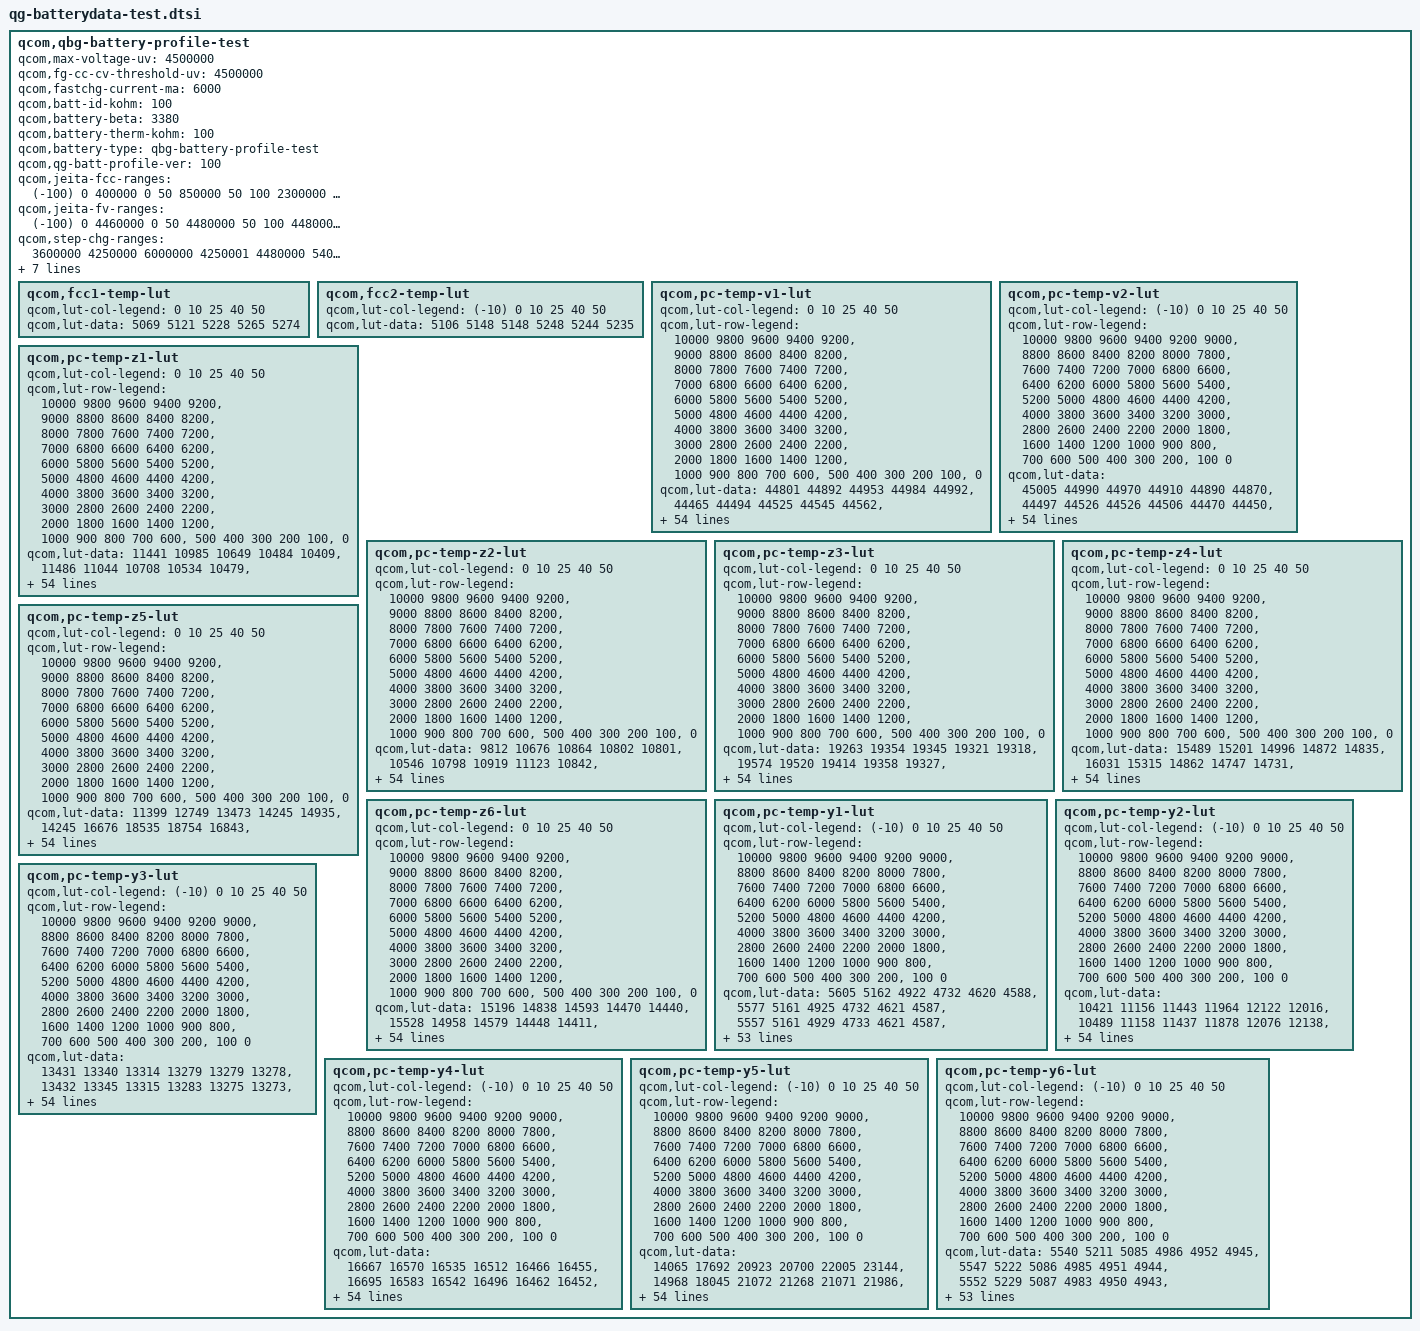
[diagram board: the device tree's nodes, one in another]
qcom,qbg-battery-profile-test {
	/* just test bsttry profile */
	qcom,max-voltage-uv = <4500000>;
	qcom,fg-cc-cv-threshold-uv = <4500000>;
	qcom,fastchg-current-ma = <6000>;
	qcom,batt-id-kohm = <100>;
	qcom,battery-beta = <3380>;
	qcom,battery-therm-kohm = <100>;
	qcom,battery-type = "qbg-battery-profile-test";
	qcom,qg-batt-profile-ver = <100>;

	qcom,jeita-fcc-ranges = <(-100)  0   400000
				0   50   850000
				50  100  2300000
				100 150  3700000
				150 350  6000000
				350 480  6000000
				480 560  2300000
				560 1500 0>;
	qcom,jeita-fv-ranges = <(-100)   0   4460000
				0   50   4480000
				50  100  4480000
				100 150  4480000
				150 350  4450000
				350 480  4450000
				480 560  4100000
				560 1500 4100000>;
	qcom,step-chg-ranges = <3600000  4250000  6000000
				4250001  4480000  5400000
				4480001  4500000  3920000>;
	qcom,vbat-avg-based-step-chg;
	qcom,taper-fcc;

	/* COOL = 15 DegC, WARM = 48 DegC */
	qcom,jeita-soft-thresholds = <0x2554 0x0E8D>;
	/* COLD = -10 DegC, HOT = 56 DegC */
	qcom,jeita-hard-thresholds = <0x43D5 0x0B9B>;
	/* COOL hys = 18 DegC, WARM hys = 45 DegC */
	qcom,jeita-soft-hys-thresholds = <0x225F 0x0FDC>;

	qcom,jeita-soft-fcc-ua = <5400000 2500000>;
	qcom,jeita-soft-fv-uv = <4480000 4100000>;

		qcom,fcc1-temp-lut {
		qcom,lut-col-legend = <0 10 25 40 50>;
		qcom,lut-data = <5069 5121 5228 5265 5274>;
	};

	qcom,fcc2-temp-lut {
		qcom,lut-col-legend = <(-10) 0 10 25 40 50>;
		qcom,lut-data = <5106 5148 5148 5248 5244 5235>;
	};

	qcom,pc-temp-v1-lut {
		qcom,lut-col-legend = <0 10 25 40 50>;
		qcom,lut-row-legend = <10000 9800 9600 9400 9200>,
			<9000 8800 8600 8400 8200>,
			<8000 7800 7600 7400 7200>,
			<7000 6800 6600 6400 6200>,
			<6000 5800 5600 5400 5200>,
			<5000 4800 4600 4400 4200>,
			<4000 3800 3600 3400 3200>,
			<3000 2800 2600 2400 2200>,
			<2000 1800 1600 1400 1200>,
			<1000 900 800 700 600>,
			<500 400 300 200 100>,
			<0>;
		qcom,lut-data = <44801 44892 44953 44984 44992>,
			<44465 44494 44525 44545 44562>,
			<44212 44226 44228 44219 44227>,
			<43979 44010 43989 43970 43971>,
			<43748 43788 43771 43749 43748>,
			<43523 43560 43545 43525 43526>,
			<43285 43328 43312 43289 43292>,
			<43033 43083 43072 43048 43052>,
			<42777 42830 42820 42798 42805>,
			<42522 42576 42561 42542 42552>,
			<42266 42320 42302 42286 42298>,
			<42015 42065 42041 42030 42040>,
			<41767 41814 41787 41777 41784>,
			<41525 41566 41539 41527 41537>,
			<41292 41329 41298 41283 41297>,
			<41066 41100 41063 41048 41062>,
			<40848 40878 40835 40821 40831>,
			<40637 40665 40619 40604 40610>,
			<40436 40461 40415 40396 40400>,
			<40248 40269 40218 40195 40197>,
			<40066 40086 40040 40012 40011>,
			<39882 39896 39859 39835 39834>,
			<39701 39701 39620 39615 39626>,
			<39499 39493 39327 39330 39364>,
			<39231 39235 39098 39095 39133>,
			<38970 38957 38928 38943 38972>,
			<38811 38792 38792 38819 38836>,
			<38698 38700 38690 38704 38708>,
			<38609 38621 38605 38602 38591>,
			<38538 38539 38523 38503 38484>,
			<38477 38461 38443 38407 38389>,
			<38416 38384 38367 38319 38302>,
			<38359 38307 38292 38244 38224>,
			<38303 38240 38223 38176 38152>,
			<38249 38184 38164 38112 38085>,
			<38200 38135 38113 38052 38026>,
			<38159 38094 38066 37993 37960>,
			<38124 38059 38025 37941 37886>,
			<38077 38014 37976 37880 37804>,
			<38012 37944 37893 37793 37716>,
			<37930 37856 37782 37682 37619>,
			<37819 37752 37663 37561 37506>,
			<37677 37624 37530 37426 37369>,
			<37516 37464 37368 37269 37210>,
			<37343 37285 37205 37113 37054>,
			<37176 37122 37096 37017 36965>,
			<37118 37062 37068 36995 36942>,
			<37055 37026 37046 36979 36927>,
			<36991 36979 37024 36953 36903>,
			<36900 36921 36965 36854 36792>,
			<36596 36773 36716 36541 36467>,
			<32672 36361 36259 36058 35980>,
			<31829 32282 35635 35429 35346>,
			<31223 31101 34746 34553 34462>,
			<30548 30360 33258 33127 33037>,
			<30000 30000 30000 30000 30000>;
	};

	qcom,pc-temp-v2-lut {
		qcom,lut-col-legend = <(-10) 0 10 25 40 50>;
		qcom,lut-row-legend = <10000 9800 9600 9400 9200 9000>,
			<8800 8600 8400 8200 8000 7800>,
			<7600 7400 7200 7000 6800 6600>,
			<6400 6200 6000 5800 5600 5400>,
			<5200 5000 4800 4600 4400 4200>,
			<4000 3800 3600 3400 3200 3000>,
			<2800 2600 2400 2200 2000 1800>,
			<1600 1400 1200 1000 900 800>,
			<700 600 500 400 300 200>,
			<100 0>;
		qcom,lut-data = <45005 44990 44970 44910 44890 44870>,
			<44497 44526 44526 44506 44470 44450>,
			<44078 44143 44159 44163 44113 44091>,
			<43775 43865 43890 43896 43836 43811>,
			<43552 43662 43689 43683 43613 43586>,
			<43337 43460 43485 43462 43387 43359>,
			<43103 43232 43257 43224 43149 43121>,
			<42867 42996 43021 42981 42907 42879>,
			<42625 42754 42777 42730 42657 42629>,
			<42375 42504 42523 42473 42401 42374>,
			<42126 42255 42269 42217 42146 42119>,
			<41877 42006 42016 41958 41891 41865>,
			<41631 41758 41766 41704 41639 41615>,
			<41402 41516 41521 41454 41392 41372>,
			<41186 41278 41282 41209 41151 41134>,
			<40965 41050 41049 40973 40919 40902>,
			<40736 40838 40820 40744 40693 40677>,
			<40497 40631 40600 40525 40477 40461>,
			<40238 40421 40396 40317 40271 40254>,
			<39960 40208 40195 40109 40070 40055>,
			<39698 39974 39965 39902 39881 39871>,
			<39457 39691 39701 39692 39691 39691>,
			<39231 39410 39449 39455 39463 39470>,
			<39013 39188 39214 39188 39188 39195>,
			<38806 38994 39001 38966 38965 38967>,
			<38630 38824 38828 38799 38804 38807>,
			<38480 38674 38684 38658 38669 38672>,
			<38353 38537 38553 38532 38547 38551>,
			<38253 38410 38433 38422 38437 38442>,
			<38169 38294 38323 38319 38336 38341>,
			<38094 38187 38222 38222 38245 38247>,
			<38026 38085 38128 38134 38162 38161>,
			<37963 37997 38042 38055 38089 38088>,
			<37901 37932 37962 37982 38020 38019>,
			<37841 37880 37889 37913 37943 37939>,
			<37776 37830 37825 37848 37862 37847>,
			<37706 37783 37765 37776 37772 37747>,
			<37631 37733 37701 37693 37665 37628>,
			<37548 37670 37631 37605 37559 37510>,
			<37457 37596 37551 37516 37470 37417>,
			<37356 37500 37449 37420 37384 37330>,
			<37242 37368 37329 37310 37279 37221>,
			<37120 37222 37186 37181 37157 37097>,
			<36993 37063 37021 37030 37017 36959>,
			<36885 36915 36882 36888 36880 36831>,
			<36780 36801 36805 36843 36854 36802>,
			<36729 36750 36766 36817 36834 36784>,
			<36674 36703 36715 36775 36805 36758>,
			<36660 36651 36646 36696 36747 36696>,
			<36570 36589 36456 36480 36546 36496>,
			<36408 36484 36064 36017 36112 36050>,
			<36289 36266 35471 35355 35521 35476>,
			<35407 36276 34689 34382 34735 34708>,
			<31338 35839 33955 33304 33541 33579>,
			<30264 30665 32502 32805 31731 31656>,
			<29252 29324 28120 29068 27613 27531>;
	};

	qcom,pc-temp-z1-lut {
		qcom,lut-col-legend = <0 10 25 40 50>;
		qcom,lut-row-legend = <10000 9800 9600 9400 9200>,
			<9000 8800 8600 8400 8200>,
			<8000 7800 7600 7400 7200>,
			<7000 6800 6600 6400 6200>,
			<6000 5800 5600 5400 5200>,
			<5000 4800 4600 4400 4200>,
			<4000 3800 3600 3400 3200>,
			<3000 2800 2600 2400 2200>,
			<2000 1800 1600 1400 1200>,
			<1000 900 800 700 600>,
			<500 400 300 200 100>,
			<0>;
		qcom,lut-data = <11441 10985 10649 10484 10409>,
			<11486 11044 10708 10534 10479>,
			<11487 11042 10711 10536 10480>,
			<11488 11052 10706 10528 10475>,
			<11497 11059 10707 10526 10475>,
			<11516 11063 10707 10526 10475>,
			<11520 11066 10704 10526 10475>,
			<11501 11064 10700 10526 10476>,
			<11481 11058 10695 10525 10476>,
			<11473 11053 10691 10522 10477>,
			<11467 11046 10691 10521 10477>,
			<11462 11041 10691 10521 10477>,
			<11458 11038 10692 10522 10478>,
			<11456 11036 10692 10522 10478>,
			<11466 11036 10692 10523 10481>,
			<11485 11038 10694 10525 10483>,
			<11486 11039 10699 10527 10485>,
			<11474 11037 10704 10530 10487>,
			<11467 11035 10710 10532 10489>,
			<11468 11037 10713 10535 10492>,
			<11472 11046 10713 10538 10495>,
			<11476 11053 10713 10541 10499>,
			<11481 11059 10713 10543 10500>,
			<11483 11063 10716 10544 10500>,
			<11479 11063 10719 10545 10501>,
			<11473 11062 10724 10548 10502>,
			<11477 11062 10728 10553 10505>,
			<11493 11068 10731 10556 10508>,
			<11500 11072 10735 10559 10512>,
			<11495 11072 10738 10562 10515>,
			<11489 11070 10741 10565 10518>,
			<11490 11071 10745 10568 10521>,
			<11495 11079 10753 10573 10523>,
			<11496 11083 10759 10578 10525>,
			<11487 11082 10760 10579 10528>,
			<11478 11080 10759 10579 10531>,
			<11487 11080 10759 10579 10534>,
			<11511 11081 10763 10584 10535>,
			<11519 11083 10769 10589 10536>,
			<11511 11083 10777 10592 10538>,
			<11505 11084 10787 10594 10540>,
			<11513 11089 10790 10597 10542>,
			<11525 11099 10791 10602 10544>,
			<11526 11115 10795 10604 10547>,
			<11526 11120 10800 10605 10549>,
			<11541 11109 10803 10609 10552>,
			<11560 11113 10807 10610 10553>,
			<11524 11097 10805 10612 10553>,
			<11524 11102 10805 10615 10554>,
			<11517 11103 10814 10618 10557>,
			<11516 11106 10814 10621 10561>,
			<11528 11099 10825 10625 10567>,
			<11534 11095 10839 10637 10574>,
			<11534 11104 10857 10650 10585>,
			<11534 11104 10857 10650 10585>,
			<11534 11104 10857 10650 10585>;
	};

	qcom,pc-temp-z2-lut {
		qcom,lut-col-legend = <0 10 25 40 50>;
		qcom,lut-row-legend = <10000 9800 9600 9400 9200>,
			<9000 8800 8600 8400 8200>,
			<8000 7800 7600 7400 7200>,
			<7000 6800 6600 6400 6200>,
			<6000 5800 5600 5400 5200>,
			<5000 4800 4600 4400 4200>,
			<4000 3800 3600 3400 3200>,
			<3000 2800 2600 2400 2200>,
			<2000 1800 1600 1400 1200>,
			<1000 900 800 700 600>,
			<500 400 300 200 100>,
			<0>;
		qcom,lut-data = <9812 10676 10864 10802 10801>,
			<10546 10798 10919 11123 10842>,
			<10565 10804 10959 11232 10966>,
			<10582 10736 10881 11082 11273>,
			<10564 10676 10820 11017 11207>,
			<10513 10623 10760 10997 11157>,
			<10470 10579 10691 10996 11171>,
			<10433 10542 10657 10996 11192>,
			<10404 10514 10672 11001 11187>,
			<10387 10514 10698 11018 11158>,
			<10374 10547 10715 11032 11150>,
			<10375 10579 10727 11040 11229>,
			<10403 10597 10744 11051 11302>,
			<10431 10612 10777 11090 11226>,
			<10447 10634 10811 11138 11076>,
			<10461 10661 10833 11116 11053>,
			<10476 10688 10852 11000 11108>,
			<10492 10713 10884 10951 11188>,
			<10510 10736 10940 11026 11353>,
			<10536 10757 10984 11128 11506>,
			<10559 10777 10999 11192 11530>,
			<10561 10782 11014 11250 11538>,
			<10557 10770 11071 11352 11552>,
			<10555 10760 11192 11545 11576>,
			<10558 10762 11229 11640 11610>,
			<10563 10768 11131 11512 11703>,
			<10562 10768 11020 11357 11801>,
			<10559 10751 10964 11375 11798>,
			<10558 10738 10925 11454 11735>,
			<10566 10760 10957 11469 11638>,
			<10576 10796 11161 11363 11416>,
			<10576 10805 11274 11245 11213>,
			<10575 10806 11166 11165 11121>,
			<10575 10807 11037 11106 11061>,
			<10583 10796 11026 11144 11082>,
			<10592 10782 11026 11337 11249>,
			<10592 10782 11030 11510 11472>,
			<10592 10790 11083 11657 11856>,
			<10592 10799 11143 11745 12157>,
			<10595 10805 11185 11737 12145>,
			<10599 10813 11217 11710 12067>,
			<10603 10823 11204 11680 11932>,
			<10608 10836 11140 11638 11666>,
			<10654 10850 11126 11442 11587>,
			<10659 10946 11134 11200 11559>,
			<10552 11111 11206 11274 11489>,
			<9889 11087 11180 11259 11528>,
			<9815 11033 11121 11282 11525>,
			<9735 10981 11080 11333 11734>,
			<10057 10901 11065 11521 11696>,
			<11666 10812 11261 11177 11100>,
			<65535 10708 11152 10851 10842>,
			<65535 65535 10747 10737 10849>,
			<9707 10720 10599 10612 10799>,
			<9707 10720 10599 10612 10799>,
			<9707 10720 10599 10612 10799>;
	};

	qcom,pc-temp-z3-lut {
		qcom,lut-col-legend = <0 10 25 40 50>;
		qcom,lut-row-legend = <10000 9800 9600 9400 9200>,
			<9000 8800 8600 8400 8200>,
			<8000 7800 7600 7400 7200>,
			<7000 6800 6600 6400 6200>,
			<6000 5800 5600 5400 5200>,
			<5000 4800 4600 4400 4200>,
			<4000 3800 3600 3400 3200>,
			<3000 2800 2600 2400 2200>,
			<2000 1800 1600 1400 1200>,
			<1000 900 800 700 600>,
			<500 400 300 200 100>,
			<0>;
		qcom,lut-data = <19263 19354 19345 19321 19318>,
			<19574 19520 19414 19358 19327>,
			<19641 19556 19448 19354 19327>,
			<19678 19564 19482 19406 19371>,
			<19691 19571 19487 19409 19375>,
			<19699 19578 19487 19409 19376>,
			<19706 19582 19484 19406 19375>,
			<19714 19581 19479 19400 19372>,
			<19718 19578 19467 19394 19367>,
			<19715 19572 19453 19387 19357>,
			<19706 19550 19446 19380 19353>,
			<19696 19532 19442 19373 19353>,
			<19682 19525 19437 19366 19352>,
			<19667 19520 19427 19362 19345>,
			<19655 19511 19416 19358 19331>,
			<19644 19500 19409 19351 19326>,
			<19634 19491 19403 19337 19324>,
			<19627 19484 19396 19329 19323>,
			<19619 19480 19385 19326 19321>,
			<19609 19478 19379 19324 19318>,
			<19601 19477 19376 19322 19315>,
			<19601 19477 19375 19321 19311>,
			<19607 19483 19382 19323 19311>,
			<19615 19491 19404 19336 19313>,
			<19633 19498 19411 19343 19315>,
			<19651 19505 19402 19328 19305>,
			<19651 19505 19389 19310 19290>,
			<19644 19489 19378 19309 19303>,
			<19636 19477 19368 19312 19350>,
			<19629 19477 19367 19318 19367>,
			<19622 19477 19374 19347 19359>,
			<19617 19479 19383 19367 19347>,
			<19614 19494 19401 19362 19338>,
			<19612 19503 19418 19352 19330>,
			<19612 19501 19416 19346 19323>,
			<19612 19497 19407 19341 19316>,
			<19610 19492 19398 19337 19314>,
			<19606 19486 19390 19335 19318>,
			<19601 19480 19385 19334 19322>,
			<19594 19477 19384 19335 19322>,
			<19586 19474 19384 19338 19321>,
			<19578 19465 19383 19337 19318>,
			<19567 19452 19381 19333 19310>,
			<19550 19446 19379 19326 19313>,
			<19455 19432 19375 19320 19320>,
			<19341 19407 19359 19318 19304>,
			<19273 19406 19357 19315 19302>,
			<19274 19335 19350 19310 19298>,
			<19277 19313 19331 19305 19287>,
			<19316 19313 19323 19302 19287>,
			<19524 19428 19308 19309 19313>,
			<19265 19441 19305 19329 19325>,
			<19260 19263 19324 19334 19327>,
			<21204 20903 19399 19336 19328>,
			<21204 20903 19399 19336 19328>,
			<21204 20903 19399 19336 19328>;
	};

	qcom,pc-temp-z4-lut {
		qcom,lut-col-legend = <0 10 25 40 50>;
		qcom,lut-row-legend = <10000 9800 9600 9400 9200>,
			<9000 8800 8600 8400 8200>,
			<8000 7800 7600 7400 7200>,
			<7000 6800 6600 6400 6200>,
			<6000 5800 5600 5400 5200>,
			<5000 4800 4600 4400 4200>,
			<4000 3800 3600 3400 3200>,
			<3000 2800 2600 2400 2200>,
			<2000 1800 1600 1400 1200>,
			<1000 900 800 700 600>,
			<500 400 300 200 100>,
			<0>;
		qcom,lut-data = <15489 15201 14996 14872 14835>,
			<16031 15315 14862 14747 14731>,
			<15780 15365 14913 14725 14707>,
			<15474 15170 14966 14816 14766>,
			<15308 15042 14903 14792 14749>,
			<15181 14969 14859 14767 14731>,
			<15086 14915 14830 14749 14719>,
			<15012 14872 14808 14736 14709>,
			<14955 14839 14792 14730 14707>,
			<14912 14816 14779 14727 14707>,
			<14878 14798 14766 14723 14705>,
			<14846 14785 14755 14719 14695>,
			<14812 14773 14745 14715 14686>,
			<14791 14763 14739 14707 14687>,
			<14783 14756 14732 14699 14690>,
			<14778 14751 14723 14697 14689>,
			<14773 14746 14713 14697 14680>,
			<14768 14738 14706 14696 14671>,
			<14763 14730 14701 14688 14662>,
			<14759 14721 14696 14677 14655>,
			<14755 14712 14688 14670 14652>,
			<14750 14709 14680 14664 14649>,
			<14743 14712 14694 14671 14655>,
			<14740 14719 14746 14723 14704>,
			<14781 14757 14787 14769 14750>,
			<14835 14827 14818 14794 14773>,
			<14845 14846 14835 14809 14787>,
			<14848 14842 14834 14806 14769>,
			<14848 14835 14830 14793 14706>,
			<14838 14823 14822 14772 14677>,
			<14823 14805 14801 14725 14673>,
			<14809 14784 14776 14690 14671>,
			<14796 14757 14741 14681 14667>,
			<14784 14739 14712 14676 14663>,
			<14773 14732 14704 14673 14662>,
			<14764 14727 14700 14671 14661>,
			<14757 14723 14699 14671 14662>,
			<14751 14718 14698 14673 14668>,
			<14745 14716 14698 14676 14675>,
			<14739 14717 14708 14683 14675>,
			<14733 14718 14725 14690 14675>,
			<14726 14716 14725 14691 14675>,
			<14720 14709 14714 14688 14675>,
			<14715 14702 14711 14691 14673>,
			<14757 14688 14707 14697 14665>,
			<14837 14677 14684 14670 14660>,
			<14906 14678 14677 14661 14649>,
			<14907 14748 14664 14645 14635>,
			<14905 14765 14666 14634 14630>,
			<14873 14764 14677 14650 14642>,
			<14750 14669 14725 14660 14628>,
			<17170 14744 14745 14643 14619>,
			<17342 16945 14732 14640 14620>,
			<14917 14975 14662 14645 14626>,
			<14917 14975 14662 14645 14626>,
			<14917 14975 14662 14645 14626>;
	};

	qcom,pc-temp-z5-lut {
		qcom,lut-col-legend = <0 10 25 40 50>;
		qcom,lut-row-legend = <10000 9800 9600 9400 9200>,
			<9000 8800 8600 8400 8200>,
			<8000 7800 7600 7400 7200>,
			<7000 6800 6600 6400 6200>,
			<6000 5800 5600 5400 5200>,
			<5000 4800 4600 4400 4200>,
			<4000 3800 3600 3400 3200>,
			<3000 2800 2600 2400 2200>,
			<2000 1800 1600 1400 1200>,
			<1000 900 800 700 600>,
			<500 400 300 200 100>,
			<0>;
		qcom,lut-data = <11399 12749 13473 14245 14935>,
			<14245 16676 18535 18754 16843>,
			<15388 16893 19785 21684 19186>,
			<16381 17675 19138 20534 21140>,
			<17083 18455 19765 20927 21836>,
			<17652 19283 19935 21402 22343>,
			<18354 20011 19888 21959 23071>,
			<19302 20563 19854 22404 23664>,
			<20162 20992 19865 22244 23344>,
			<20673 21113 19895 21598 21870>,
			<21094 21138 20140 21039 21298>,
			<21887 21179 20917 20524 22437>,
			<23572 21752 21242 20251 23493>,
			<24690 22521 21103 20509 22284>,
			<24777 22591 20971 20925 19889>,
			<24825 22436 21360 20638 19512>,
			<25003 22369 22192 19257 20248>,
			<25518 22908 22419 18662 21208>,
			<25887 23905 22435 19227 22448>,
			<25958 25035 22466 20194 23784>,
			<26012 26576 23419 21273 24928>,
			<26728 28725 25720 22803 25941>,
			<30150 32553 33293 25793 26237>,
			<35101 36433 50024 32449 26293>,
			<46041 39189 55335 35841 26307>,
			<56866 41400 44195 28860 22133>,
			<55956 40926 31807 19752 16311>,
			<47865 33172 26070 17432 17539>,
			<41276 26622 22115 16318 23679>,
			<36910 25219 21103 16482 26174>,
			<34165 24427 20792 20604 26294>,
			<33987 25280 20766 24715 26416>,
			<34041 30540 25779 26285 26832>,
			<34268 35350 32775 27522 27547>,
			<36728 38413 35825 29832 28310>,
			<39109 40476 37822 33330 29188>,
			<39208 40493 38196 34617 30383>,
			<39119 39663 36963 34145 32847>,
			<38889 38584 35039 33220 34813>,
			<37612 37178 32051 30947 32841>,
			<35802 35214 28500 27247 27604>,
			<34057 31459 26770 24945 24007>,
			<31933 27083 25840 23538 21501>,
			<29317 26416 24405 20827 21582>,
			<21296 26816 23522 18668 22436>,
			<13659 26918 24163 20619 19636>,
			<11995 25691 23344 20572 20604>,
			<11857 15429 22653 21574 21291>,
			<11800 13503 19336 23226 20839>,
			<12430 13355 17307 19195 17716>,
			<44007 42655 14248 16868 26044>,
			<13250 24829 13171 20640 35004>,
			<10209 10543 13883 22121 36677>,
			<19124 13137 25007 21879 34124>,
			<19124 13137 25007 21879 34124>,
			<19124 13137 25007 21879 34124>;
	};

	qcom,pc-temp-z6-lut {
		qcom,lut-col-legend = <0 10 25 40 50>;
		qcom,lut-row-legend = <10000 9800 9600 9400 9200>,
			<9000 8800 8600 8400 8200>,
			<8000 7800 7600 7400 7200>,
			<7000 6800 6600 6400 6200>,
			<6000 5800 5600 5400 5200>,
			<5000 4800 4600 4400 4200>,
			<4000 3800 3600 3400 3200>,
			<3000 2800 2600 2400 2200>,
			<2000 1800 1600 1400 1200>,
			<1000 900 800 700 600>,
			<500 400 300 200 100>,
			<0>;
		qcom,lut-data = <15196 14838 14593 14470 14440>,
			<15528 14958 14579 14448 14411>,
			<15420 14988 14611 14436 14401>,
			<15282 14897 14648 14499 14449>,
			<15197 14835 14621 14490 14445>,
			<15127 14799 14600 14480 14439>,
			<15073 14770 14585 14471 14433>,
			<15031 14746 14570 14462 14427>,
			<14996 14725 14556 14455 14422>,
			<14964 14704 14542 14450 14418>,
			<14937 14683 14533 14445 14414>,
			<14910 14667 14525 14439 14410>,
			<14882 14657 14518 14433 14406>,
			<14862 14648 14509 14428 14402>,
			<14850 14640 14501 14423 14397>,
			<14842 14631 14493 14417 14392>,
			<14835 14623 14486 14411 14388>,
			<14828 14616 14479 14405 14384>,
			<14822 14611 14472 14400 14379>,
			<14816 14606 14466 14395 14375>,
			<14811 14602 14462 14392 14372>,
			<14811 14601 14459 14389 14369>,
			<14812 14606 14469 14394 14371>,
			<14815 14615 14504 14426 14396>,
			<14845 14638 14524 14445 14414>,
			<14880 14673 14532 14447 14417>,
			<14884 14681 14535 14447 14419>,
			<14883 14674 14533 14446 14418>,
			<14881 14665 14526 14442 14417>,
			<14874 14659 14521 14438 14414>,
			<14865 14653 14517 14434 14409>,
			<14858 14649 14513 14430 14403>,
			<14852 14645 14510 14424 14397>,
			<14848 14642 14506 14418 14391>,
			<14845 14640 14502 14413 14387>,
			<14843 14638 14497 14409 14383>,
			<14841 14635 14493 14407 14381>,
			<14839 14630 14490 14408 14386>,
			<14838 14629 14488 14409 14391>,
			<14838 14630 14493 14412 14391>,
			<14838 14632 14502 14417 14391>,
			<14837 14630 14503 14418 14390>,
			<14836 14625 14498 14414 14386>,
			<14834 14623 14498 14414 14387>,
			<14818 14617 14497 14413 14389>,
			<14799 14602 14481 14402 14378>,
			<14797 14603 14477 14397 14373>,
			<14798 14597 14469 14387 14364>,
			<14801 14595 14461 14379 14356>,
			<14810 14597 14462 14385 14362>,
			<14861 14618 14478 14396 14372>,
			<15755 14659 14490 14402 14376>,
			<15847 15522 14500 14405 14379>,
			<15836 15620 14519 14411 14386>,
			<15836 15620 14519 14411 14386>,
			<15836 15620 14519 14411 14386>;
	};

	qcom,pc-temp-y1-lut {
		qcom,lut-col-legend = <(-10) 0 10 25 40 50>;
		qcom,lut-row-legend = <10000 9800 9600 9400 9200 9000>,
			<8800 8600 8400 8200 8000 7800>,
			<7600 7400 7200 7000 6800 6600>,
			<6400 6200 6000 5800 5600 5400>,
			<5200 5000 4800 4600 4400 4200>,
			<4000 3800 3600 3400 3200 3000>,
			<2800 2600 2400 2200 2000 1800>,
			<1600 1400 1200 1000 900 800>,
			<700 600 500 400 300 200>,
			<100 0>;
		qcom,lut-data = <5605 5162 4922 4732 4620 4588>,
			<5577 5161 4925 4732 4621 4587>,
			<5557 5161 4929 4733 4621 4587>,
			<5544 5161 4932 4733 4621 4587>,
			<5537 5161 4934 4732 4621 4586>,
			<5536 5162 4935 4732 4621 4586>,
			<5544 5163 4934 4732 4619 4587>,
			<5554 5165 4933 4731 4617 4587>,
			<5558 5165 4933 4731 4616 4587>,
			<5559 5164 4933 4731 4615 4586>,
			<5560 5164 4932 4730 4615 4586>,
			<5560 5165 4932 4730 4615 4586>,
			<5560 5166 4930 4730 4615 4586>,
			<5560 5166 4930 4730 4615 4587>,
			<5561 5167 4929 4729 4615 4588>,
			<5561 5167 4928 4729 4616 4589>,
			<5563 5167 4928 4729 4617 4591>,
			<5566 5167 4928 4729 4618 4591>,
			<5569 5168 4928 4727 4618 4590>,
			<5572 5170 4928 4726 4618 4589>,
			<5574 5173 4928 4728 4618 4589>,
			<5576 5177 4928 4732 4618 4591>,
			<5577 5182 4929 4734 4619 4592>,
			<5574 5187 4931 4734 4621 4593>,
			<5569 5191 4932 4735 4622 4594>,
			<5566 5191 4932 4739 4624 4594>,
			<5565 5191 4930 4743 4625 4594>,
			<5563 5191 4930 4743 4626 4595>,
			<5553 5192 4937 4742 4626 4597>,
			<5542 5193 4944 4742 4627 4599>,
			<5538 5191 4940 4742 4629 4600>,
			<5536 5185 4931 4743 4632 4601>,
			<5536 5180 4929 4744 4634 4602>,
			<5551 5176 4931 4746 4635 4604>,
			<5567 5172 4932 4749 4637 4605>,
			<5568 5169 4933 4755 4637 4607>,
			<5566 5167 4933 4758 4639 4609>,
			<5563 5166 4935 4756 4641 4610>,
			<5558 5167 4943 4754 4643 4611>,
			<5554 5167 4948 4753 4644 4611>,
			<5554 5164 4948 4752 4645 4610>,
			<5555 5163 4948 4759 4646 4611>,
			<5540 5166 4937 4764 4646 4615>,
			<5526 5163 4938 4766 4649 4616>,
			<5551 5170 4949 4762 4648 4616>,
			<5571 5171 4961 4763 4652 4618>,
			<5566 5177 4944 4772 4654 4619>,
			<5577 5185 4944 4770 4653 4618>,
			<5600 5215 4957 4772 4654 4620>,
			<5681 5223 4960 4780 4656 4620>,
			<5764 5254 4974 4788 4658 4621>,
			<5878 5319 4983 4801 4664 4627>,
			<6103 5452 5013 4803 4671 4634>,
			<6104 5601 5088 4833 4686 4645>,
			<6104 5601 5088 4833 4686 4645>,
			<6104 5601 5088 4833 4686 4645>;
	};

	qcom,pc-temp-y2-lut {
		qcom,lut-col-legend = <(-10) 0 10 25 40 50>;
		qcom,lut-row-legend = <10000 9800 9600 9400 9200 9000>,
			<8800 8600 8400 8200 8000 7800>,
			<7600 7400 7200 7000 6800 6600>,
			<6400 6200 6000 5800 5600 5400>,
			<5200 5000 4800 4600 4400 4200>,
			<4000 3800 3600 3400 3200 3000>,
			<2800 2600 2400 2200 2000 1800>,
			<1600 1400 1200 1000 900 800>,
			<700 600 500 400 300 200>,
			<100 0>;
		qcom,lut-data = <10421 11156 11443 11964 12122 12016>,
			<10489 11158 11437 11878 12076 12138>,
			<10573 11156 11425 11795 12020 12187>,
			<10658 11153 11407 11718 11956 12183>,
			<10728 11147 11385 11652 11884 12143>,
			<10765 11140 11359 11603 11804 12080>,
			<10780 11130 11324 11565 11690 11929>,
			<10790 11120 11291 11535 11613 11781>,
			<10802 11109 11275 11511 11640 11715>,
			<10814 11098 11264 11492 11696 11671>,
			<10830 11096 11261 11486 11701 11666>,
			<10853 11113 11268 11483 11658 11686>,
			<10882 11136 11281 11483 11633 11709>,
			<10920 11157 11306 11532 11650 11730>,
			<10964 11180 11349 11615 11682 11755>,
			<10997 11207 11397 11683 11712 11806>,
			<11020 11243 11455 11750 11748 11893>,
			<11038 11274 11502 11821 11797 11959>,
			<11053 11299 11533 11899 11872 11995>,
			<11064 11316 11554 11968 11968 12041>,
			<11068 11320 11554 12028 12135 12184>,
			<11070 11321 11542 12072 12309 12369>,
			<11070 11324 11536 12034 12316 12395>,
			<10661 11357 11547 11855 12227 12356>,
			<9986 11393 11565 11775 12150 12317>,
			<9809 11397 11584 11834 12094 12284>,
			<9769 11398 11607 11899 12059 12260>,
			<9745 11399 11632 11911 12146 12324>,
			<9727 11400 11667 11916 12355 12530>,
			<9714 11401 11691 11938 12404 12706>,
			<9706 11403 11694 12030 12330 12870>,
			<9700 11406 11695 12103 12280 12957>,
			<9695 11398 11695 12131 12473 12955>,
			<9690 11333 11688 12147 12747 12947>,
			<9686 11253 11677 12148 12761 12907>,
			<9682 11193 11657 12148 12677 12777>,
			<9678 11115 11624 12146 12558 12701>,
			<9675 10850 11579 12125 12315 12687>,
			<9672 10185 11511 12087 12135 12673>,
			<9671 9817 11428 11974 12204 12559>,
			<9669 9746 11321 11869 12298 12370>,
			<9667 9710 11197 11880 12251 12310>,
			<9664 9692 11061 11903 12064 12169>,
			<9663 9679 10308 11835 12258 12117>,
			<9667 9671 10168 11636 11975 12234>,
			<9764 9662 9826 11527 11888 11887>,
			<9671 9670 9724 11496 11824 11756>,
			<9663 9784 9682 11430 11752 11731>,
			<9657 9691 9664 11324 11650 11596>,
			<9658 9666 9697 11133 11616 11661>,
			<9652 9656 9700 10828 11491 11524>,
			<9651 9652 9676 10430 11407 11486>,
			<9651 9652 9657 10031 11355 11516>,
			<9651 9652 9655 9835 11216 11412>,
			<9651 9652 9655 9835 11216 11412>,
			<9651 9652 9655 9835 11216 11412>;
	};

	qcom,pc-temp-y3-lut {
		qcom,lut-col-legend = <(-10) 0 10 25 40 50>;
		qcom,lut-row-legend = <10000 9800 9600 9400 9200 9000>,
			<8800 8600 8400 8200 8000 7800>,
			<7600 7400 7200 7000 6800 6600>,
			<6400 6200 6000 5800 5600 5400>,
			<5200 5000 4800 4600 4400 4200>,
			<4000 3800 3600 3400 3200 3000>,
			<2800 2600 2400 2200 2000 1800>,
			<1600 1400 1200 1000 900 800>,
			<700 600 500 400 300 200>,
			<100 0>;
		qcom,lut-data = <13431 13340 13314 13279 13279 13278>,
			<13432 13345 13315 13283 13275 13273>,
			<13436 13349 13317 13286 13273 13271>,
			<13440 13354 13318 13288 13272 13269>,
			<13443 13357 13319 13289 13271 13268>,
			<13444 13360 13321 13289 13271 13268>,
			<13444 13362 13322 13288 13272 13270>,
			<13444 13363 13323 13287 13273 13271>,
			<13443 13363 13323 13288 13276 13272>,
			<13442 13363 13322 13291 13280 13273>,
			<13440 13362 13322 13293 13281 13273>,
			<13437 13362 13322 13294 13282 13274>,
			<13436 13361 13322 13294 13283 13274>,
			<13435 13359 13323 13294 13283 13277>,
			<13434 13358 13323 13294 13283 13280>,
			<13433 13358 13323 13295 13284 13280>,
			<13428 13359 13320 13296 13287 13280>,
			<13420 13360 13318 13296 13288 13280>,
			<13413 13358 13319 13295 13287 13279>,
			<13406 13355 13321 13294 13287 13278>,
			<13400 13351 13320 13295 13287 13280>,
			<13394 13347 13318 13296 13287 13284>,
			<13388 13343 13315 13295 13286 13283>,
			<13375 13338 13310 13290 13277 13274>,
			<13362 13334 13307 13286 13273 13269>,
			<13360 13332 13307 13283 13273 13269>,
			<13362 13330 13307 13281 13273 13269>,
			<13365 13329 13306 13282 13272 13269>,
			<13368 13328 13305 13284 13272 13271>,
			<13373 13326 13304 13285 13272 13271>,
			<13381 13321 13305 13286 13273 13270>,
			<13395 13313 13305 13286 13273 13269>,
			<13411 13312 13305 13286 13274 13270>,
			<13429 13317 13305 13287 13275 13272>,
			<13450 13323 13305 13287 13275 13272>,
			<13477 13329 13305 13286 13275 13271>,
			<13510 13334 13306 13286 13274 13270>,
			<13550 13338 13307 13285 13272 13270>,
			<13602 13341 13308 13285 13271 13269>,
			<13666 13347 13310 13283 13271 13269>,
			<13743 13361 13311 13282 13272 13271>,
			<13846 13383 13313 13284 13273 13269>,
			<13990 13423 13314 13284 13274 13269>,
			<14239 13474 13310 13281 13274 13271>,
			<14673 13573 13311 13280 13270 13269>,
			<15227 13968 13342 13290 13277 13271>,
			<13639 14736 13379 13295 13278 13274>,
			<13741 15160 13465 13299 13281 13279>,
			<14197 13672 13762 13306 13285 13279>,
			<16850 14006 14862 13310 13285 13277>,
			<30484 17968 13463 13315 13282 13276>,
			<57634 26586 13773 13346 13283 13279>,
			<65535 41461 15576 13608 13287 13281>,
			<65535 62827 18981 13401 13294 13285>,
			<65535 62827 18981 13401 13294 13285>,
			<65535 62827 18981 13401 13294 13285>;
	};

	qcom,pc-temp-y4-lut {
		qcom,lut-col-legend = <(-10) 0 10 25 40 50>;
		qcom,lut-row-legend = <10000 9800 9600 9400 9200 9000>,
			<8800 8600 8400 8200 8000 7800>,
			<7600 7400 7200 7000 6800 6600>,
			<6400 6200 6000 5800 5600 5400>,
			<5200 5000 4800 4600 4400 4200>,
			<4000 3800 3600 3400 3200 3000>,
			<2800 2600 2400 2200 2000 1800>,
			<1600 1400 1200 1000 900 800>,
			<700 600 500 400 300 200>,
			<100 0>;
		qcom,lut-data = <16667 16570 16535 16512 16466 16455>,
			<16695 16583 16542 16496 16462 16452>,
			<16738 16604 16548 16485 16458 16449>,
			<16784 16628 16553 16477 16454 16446>,
			<16821 16646 16556 16473 16451 16444>,
			<16838 16652 16557 16472 16451 16442>,
			<16843 16651 16555 16477 16452 16441>,
			<16845 16649 16552 16482 16453 16440>,
			<16847 16646 16552 16485 16452 16441>,
			<16848 16644 16553 16486 16449 16444>,
			<16849 16643 16553 16489 16449 16446>,
			<16857 16650 16557 16495 16453 16450>,
			<16869 16661 16563 16503 16459 16452>,
			<16880 16676 16571 16512 16466 16452>,
			<16891 16697 16582 16522 16473 16453>,
			<16893 16719 16597 16532 16477 16455>,
			<16874 16743 16619 16543 16480 16461>,
			<16845 16756 16643 16558 16485 16469>,
			<16811 16746 16671 16584 16496 16479>,
			<16769 16724 16695 16601 16510 16490>,
			<16733 16692 16689 16603 16529 16501>,
			<16698 16641 16647 16603 16548 16511>,
			<16680 16601 16602 16587 16540 16506>,
			<16688 16575 16553 16518 16493 16475>,
			<16702 16557 16515 16482 16465 16455>,
			<16700 16552 16506 16477 16458 16450>,
			<16681 16549 16501 16475 16455 16447>,
			<16671 16546 16500 16477 16457 16448>,
			<16671 16541 16503 16483 16463 16451>,
			<16672 16538 16506 16490 16470 16455>,
			<16672 16539 16511 16497 16480 16464>,
			<16672 16540 16515 16504 16489 16474>,
			<16672 16542 16517 16513 16499 16482>,
			<16676 16543 16519 16522 16506 16489>,
			<16683 16545 16520 16527 16505 16488>,
			<16689 16554 16524 16530 16499 16482>,
			<16696 16569 16531 16530 16490 16474>,
			<16702 16591 16539 16515 16473 16461>,
			<16711 16623 16550 16499 16461 16450>,
			<16717 16636 16555 16495 16461 16448>,
			<16715 16637 16553 16493 16461 16447>,
			<16713 16637 16549 16493 16460 16448>,
			<16715 16634 16541 16492 16460 16449>,
			<16715 16631 16560 16482 16454 16445>,
			<16704 16611 16547 16470 16443 16433>,
			<16406 16625 16556 16482 16453 16448>,
			<21138 16621 16575 16495 16462 16452>,
			<21830 16431 16605 16512 16467 16451>,
			<25523 21961 16650 16538 16480 16475>,
			<17705 17391 16677 16535 16467 16471>,
			<21018 17831 20772 16538 16453 16446>,
			<24098 20508 17068 16600 16456 16449>,
			<16647 26588 17494 16892 16469 16460>,
			<16898 43522 19598 19574 16506 16501>,
			<16898 43522 19598 19574 16506 16501>,
			<16898 43522 19598 19574 16506 16501>;
	};

	qcom,pc-temp-y5-lut {
		qcom,lut-col-legend = <(-10) 0 10 25 40 50>;
		qcom,lut-row-legend = <10000 9800 9600 9400 9200 9000>,
			<8800 8600 8400 8200 8000 7800>,
			<7600 7400 7200 7000 6800 6600>,
			<6400 6200 6000 5800 5600 5400>,
			<5200 5000 4800 4600 4400 4200>,
			<4000 3800 3600 3400 3200 3000>,
			<2800 2600 2400 2200 2000 1800>,
			<1600 1400 1200 1000 900 800>,
			<700 600 500 400 300 200>,
			<100 0>;
		qcom,lut-data = <14065 17692 20923 20700 22005 23144>,
			<14968 18045 21072 21268 21071 21986>,
			<15963 18725 21103 21512 19672 20554>,
			<16919 19489 21041 21485 18199 19183>,
			<17708 20091 20914 21244 17044 18206>,
			<18203 20293 20746 20732 16572 17948>,
			<18518 20278 20535 18284 16416 18216>,
			<18705 20241 20222 16190 16348 18469>,
			<18657 19960 19532 16280 17299 18283>,
			<18449 19154 18318 16563 19201 17773>,
			<18363 18422 17454 16544 19509 17273>,
			<18455 17733 16927 16033 18766 16693>,
			<18648 17268 16513 15472 17894 16425>,
			<19208 17138 16169 14912 16899 17426>,
			<20334 17065 15881 14494 16120 18704>,
			<21165 17222 15609 14457 16262 18554>,
			<21797 18482 15317 14452 16832 17559>,
			<22148 20014 15178 14457 16950 16571>,
			<22166 21574 16113 14544 16160 15482>,
			<22174 22990 18019 14727 15538 14829>,
			<22160 23527 20087 16623 16057 15989>,
			<22011 23815 22672 19828 17189 18155>,
			<21719 23879 23700 21343 18222 18773>,
			<19177 22945 22926 22269 19327 18940>,
			<15249 21787 22054 22472 19747 18985>,
			<14053 21454 22097 20218 19680 18720>,
			<13700 21285 22407 17949 19532 18417>,
			<13437 21201 22471 18240 18990 18484>,
			<13139 21170 21866 19155 17925 18722>,
			<12927 21127 21335 19573 17364 18649>,
			<12971 19548 21804 19711 17073 17187>,
			<13241 16523 22772 19858 16956 16078>,
			<13465 15965 23041 20092 17493 16574>,
			<13592 17044 23070 20375 18481 17633>,
			<13697 18327 23079 20735 19263 18630>,
			<13794 19671 22726 21170 20000 19725>,
			<13883 20803 22167 21306 20202 20130>,
			<13965 20210 21987 21230 19596 19965>,
			<14049 17251 21930 21065 18771 19797>,
			<14116 15405 21814 19605 18041 19885>,
			<14161 14870 21250 18003 17566 20035>,
			<14186 14721 20416 18201 18046 18007>,
			<13574 14823 19312 17959 17963 16913>,
			<13258 13811 15362 17686 18618 18418>,
			<12991 13658 14456 17484 17711 20181>,
			<65535 13542 14766 18917 19231 16995>,
			<14522 14337 14317 18574 17378 17419>,
			<9474 65535 14067 18197 17328 21131>,
			<9943 59835 13725 18703 20892 20867>,
			<9986 11941 17362 19601 22725 20621>,
			<9242 10006 10143 19080 21738 21475>,
			<9812 9315 13899 17545 21644 25379>,
			<23383 9108 11027 13505 25226 27411>,
			<18926 8945 9535 10880 25244 26520>,
			<18926 8945 9535 10880 25244 26520>,
			<18926 8945 9535 10880 25244 26520>;
	};

	qcom,pc-temp-y6-lut {
		qcom,lut-col-legend = <(-10) 0 10 25 40 50>;
		qcom,lut-row-legend = <10000 9800 9600 9400 9200 9000>,
			<8800 8600 8400 8200 8000 7800>,
			<7600 7400 7200 7000 6800 6600>,
			<6400 6200 6000 5800 5600 5400>,
			<5200 5000 4800 4600 4400 4200>,
			<4000 3800 3600 3400 3200 3000>,
			<2800 2600 2400 2200 2000 1800>,
			<1600 1400 1200 1000 900 800>,
			<700 600 500 400 300 200>,
			<100 0>;
		qcom,lut-data = <5540 5211 5085 4986 4952 4945>,
			<5547 5222 5086 4985 4951 4944>,
			<5552 5229 5087 4983 4950 4943>,
			<5554 5233 5087 4982 4949 4942>,
			<5555 5234 5086 4981 4948 4942>,
			<5555 5234 5085 4981 4948 4942>,
			<5552 5231 5083 4980 4948 4942>,
			<5545 5225 5079 4980 4949 4943>,
			<5539 5220 5076 4980 4949 4943>,
			<5532 5216 5072 4980 4949 4944>,
			<5528 5213 5070 4981 4950 4944>,
			<5526 5209 5068 4981 4951 4945>,
			<5525 5206 5067 4983 4952 4946>,
			<5526 5206 5068 4984 4953 4947>,
			<5529 5208 5069 4985 4955 4948>,
			<5531 5211 5072 4988 4956 4949>,
			<5529 5220 5075 4991 4958 4950>,
			<5526 5229 5080 4995 4961 4952>,
			<5518 5230 5089 5001 4963 4954>,
			<5499 5230 5099 5007 4966 4957>,
			<5483 5229 5098 5011 4970 4960>,
			<5471 5209 5086 5014 4977 4966>,
			<5460 5183 5073 5014 4980 4968>,
			<5450 5173 5058 4998 4968 4959>,
			<5440 5166 5047 4980 4954 4948>,
			<5436 5164 5044 4978 4952 4946>,
			<5439 5163 5043 4977 4951 4946>,
			<5443 5163 5043 4977 4951 4946>,
			<5450 5163 5044 4978 4952 4947>,
			<5463 5164 5046 4979 4953 4948>,
			<5478 5165 5047 4981 4954 4949>,
			<5496 5166 5049 4984 4956 4950>,
			<5516 5168 5051 4987 4958 4951>,
			<5537 5173 5052 4989 4961 4954>,
			<5560 5186 5054 4990 4962 4955>,
			<5586 5199 5056 4990 4961 4953>,
			<5617 5213 5059 4990 4958 4950>,
			<5651 5230 5063 4988 4956 4948>,
			<5691 5248 5067 4983 4953 4947>,
			<5735 5267 5071 4981 4952 4947>,
			<5783 5287 5077 4982 4953 4948>,
			<5835 5307 5085 4983 4954 4949>,
			<5898 5333 5097 4984 4953 4948>,
			<5980 5369 5108 4984 4953 4947>,
			<6097 5419 5109 4981 4950 4945>,
			<6247 5474 5139 4988 4954 4948>,
			<6372 5533 5163 4992 4956 4950>,
			<6517 5610 5199 5000 4961 4956>,
			<6724 5718 5256 5009 4974 4969>,
			<7157 5887 5326 5008 4965 4960>,
			<8621 6179 5445 5005 4959 4954>,
			<11725 6512 5797 5015 4963 4957>,
			<22164 7888 6410 5033 4967 4961>,
			<23364 12903 9479 5082 4985 4981>,
			<23364 12903 9479 5082 4985 4981>,
			<23364 12903 9479 5082 4985 4981>;
	};
};
